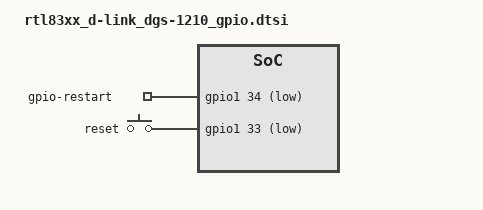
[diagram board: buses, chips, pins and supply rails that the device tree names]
// SPDX-License-Identifier: GPL-2.0-or-later OR MIT

/ {
	gpio-restart {
		compatible = "gpio-restart";
		gpios = <&gpio1 34 GPIO_ACTIVE_LOW>;
		open-source;
	};

	keys: keys {
		compatible = "gpio-keys-polled";
		poll-interval = <20>;

		reset {
			label = "reset";
			gpios = <&gpio1 33 GPIO_ACTIVE_LOW>;
			linux,code = <KEY_RESTART>;
		};
	};

	gpio1: rtl8231-gpio {
		compatible = "realtek,rtl8231-gpio";
		#gpio-cells = <2>;
		gpio-controller;
		indirect-access-bus-id = <0>;
	};
};
